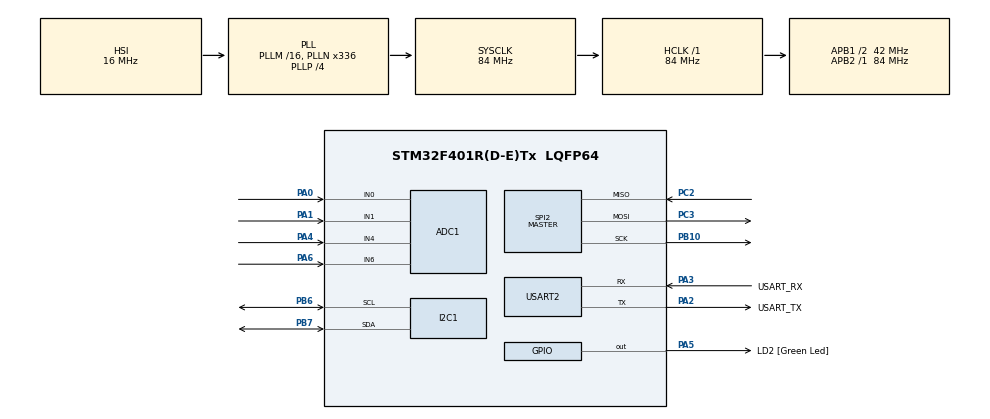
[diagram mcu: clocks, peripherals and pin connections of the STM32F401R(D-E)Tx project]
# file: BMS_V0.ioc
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ADC1.Channel-0\#ChannelRegularConversion=ADC_CHANNEL_0
ADC1.NbrOfConversionFlag=1
ADC1.Rank-0\#ChannelRegularConversion=1
ADC1.SamplingTime-0\#ChannelRegularConversion=ADC_SAMPLETIME_3CYCLES
ADC1.master=1
FREERTOS.Tasks01=Task_BMS_Main,24,128,Task_BMS_MainEntry,Default,NULL,Static,Task_BMS_MainBuffer,Task_BMS_MainControlBlock;Task_Data_Acqui,32,128,Task_Data_AcquiEntry,Default,NULL,Static,Task_Data_AcquiBuffer,Task_Data_AcquiControlBlock;Task_CAN_Tx,16,128,Task_CAN_TxEntry,Default,NULL,Static,Task_CAN_TxBuffer,Task_CAN_TxControlBlock;Task_CAN_Rx,40,128,Task_CAN_RxEntry,Default,NULL,Static,Task_CAN_RxBuffer,Task_CAN_RxControlBlock
FREERTOS.configENABLE_FPU=1
FREERTOS.configUSE_NEWLIB_REENTRANT=1
Mcu.Family=STM32F4
Mcu.Name=STM32F401R(D-E)Tx
Mcu.Package=LQFP64
NVIC.PriorityGroup=NVIC_PRIORITYGROUP_4
NVIC.TIM1_UP_TIM10_IRQn=true\:15\:0\:false\:false\:true\:false\:false\:true\:true
NVIC.TimeBase=TIM1_UP_TIM10_IRQn
NVIC.TimeBaseIP=TIM1
PA0-WKUP.Signal=ADCx_IN0
PA1.Signal=ADCx_IN1
PA13.GPIO_Label=TMS
PA13.Mode=Serial_Wire
PA13.Signal=SYS_JTMS-SWDIO
PA14.GPIO_Label=TCK
PA14.Mode=Serial_Wire
PA14.Signal=SYS_JTCK-SWCLK
PA2.GPIO_Label=USART_TX
PA2.GPIO_Mode=GPIO_MODE_AF_PP
PA2.GPIO_PuPd=GPIO_NOPULL
PA2.GPIO_Speed=GPIO_SPEED_FREQ_LOW
PA2.Mode=Asynchronous
PA2.Signal=USART2_TX
PA3.GPIO_Label=USART_RX
PA3.GPIO_Mode=GPIO_MODE_AF_PP
PA3.GPIO_PuPd=GPIO_NOPULL
PA3.GPIO_Speed=GPIO_SPEED_FREQ_LOW
PA3.Mode=Asynchronous
PA3.Signal=USART2_RX
PA4.Signal=ADCx_IN4
PA5.GPIO_Label=LD2 [Green Led]
PA5.GPIO_Mode=GPIO_MODE_OUTPUT_PP
PA5.GPIO_PuPd=GPIO_NOPULL
PA5.GPIO_Speed=GPIO_SPEED_FREQ_LOW
PA5.Signal=GPIO_Output
PA6.Signal=ADCx_IN6
PB10.Mode=Full_Duplex_Master
PB10.Signal=SPI2_SCK
PB3.GPIO_Label=SWO
PB3.Signal=SYS_JTDO-SWO
PB6.Mode=I2C
PB6.Signal=I2C1_SCL
PB7.Mode=I2C
PB7.Signal=I2C1_SDA
PC14-OSC32_IN.Mode=LSE-External-Oscillator
PC14-OSC32_IN.Signal=RCC_OSC32_IN
PC15-OSC32_OUT.Mode=LSE-External-Oscillator
PC15-OSC32_OUT.Signal=RCC_OSC32_OUT
PC2.Mode=Full_Duplex_Master
PC2.Signal=SPI2_MISO
PC3.Mode=Full_Duplex_Master
PC3.Signal=SPI2_MOSI
PH0\ -\ OSC_IN.Mode=HSE-External-Clock-Source
PH0\ -\ OSC_IN.Signal=RCC_OSC_IN
PH1\ -\ OSC_OUT.Mode=HSE-External-Clock-Source
PH1\ -\ OSC_OUT.Signal=RCC_OSC_OUT
ProjectManager.HeapSize=0x200
ProjectManager.StackSize=0x400
ProjectManager.TargetToolchain=STM32CubeIDE
RCC.48MHZClocksFreq_Value=48000000
RCC.AHBFreq_Value=84000000
RCC.APB1CLKDivider=RCC_HCLK_DIV2
RCC.APB1Freq_Value=42000000
RCC.APB1TimFreq_Value=84000000
RCC.APB2Freq_Value=84000000
RCC.APB2TimFreq_Value=84000000
RCC.CortexFreq_Value=84000000
RCC.HCLKFreq_Value=84000000
RCC.HSE_VALUE=8000000
RCC.HSI_VALUE=16000000
RCC.PLLN=336
RCC.PLLP=RCC_PLLP_DIV4
RCC.PLLQ=7
RCC.SYSCLKFreq_VALUE=84000000
RCC.SYSCLKSource=RCC_SYSCLKSOURCE_PLLCLK
RCC.VCOOutputFreq_Value=336000000
SH.ADCx_IN0.0=ADC1_IN0,IN0
SH.ADCx_IN1.0=ADC1_IN1,IN1
SH.ADCx_IN4.0=ADC1_IN4,IN4
SH.ADCx_IN6.0=ADC1_IN6,IN6
SPI2.Direction=SPI_DIRECTION_2LINES
SPI2.Mode=SPI_MODE_MASTER
SPI2.VirtualType=VM_MASTER
USART2.VirtualMode=VM_ASYNC
VP_CRC_VS_CRC.Mode=CRC_Activate
VP_FREERTOS_VS_CMSIS_V2.Mode=CMSIS_V2
VP_SYS_VS_tim1.Mode=TIM1
board=NUCLEO-F401RE

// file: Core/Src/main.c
/* USER CODE BEGIN Header */
/**
  ******************************************************************************
  * @file           : main.c
  * @brief          : Main program body
  ******************************************************************************
  * @attention
  *
  * Copyright (c) 2025 STMicroelectronics.
  * All rights reserved.
  *
  * This software is licensed under terms that can be found in the LICENSE file
  * in the root directory of this software component.
  * If no LICENSE file comes with this software, it is provided AS-IS.
  *
  ******************************************************************************
  */
/* USER CODE END Header */
#include "main.h"
#include "cmsis_os.h"

/* USER CODE BEGIN Includes */
#include "task_data_acq.h"
#include "task_bms_main.h"
#include "task_can_tx.h"
#include "task_can_rx.h"
#include "task_balance.h"
/* USER CODE END Includes */

typedef StaticTask_t osStaticThreadDef_t;

ADC_HandleTypeDef hadc1;

CRC_HandleTypeDef hcrc;

I2C_HandleTypeDef hi2c1;

SPI_HandleTypeDef hspi2;

UART_HandleTypeDef huart2;

/*============================ TASK DEFINITIONS ============================*/

/* Definitions for Task_BMS_Main */
osThreadId_t Task_BMS_MainHandle;
uint32_t Task_BMS_MainBuffer[ 128 ];
osStaticThreadDef_t Task_BMS_MainControlBlock;
const osThreadAttr_t Task_BMS_Main_attributes = {
  .name = "Task_BMS_Main",
  .cb_mem = &Task_BMS_MainControlBlock,
  .cb_size = sizeof(Task_BMS_MainControlBlock),
  .stack_mem = &Task_BMS_MainBuffer[0],
  .stack_size = sizeof(Task_BMS_MainBuffer),
  .priority = (osPriority_t) osPriorityNormal,
};

/* Definitions for Task_Data_Acqui */
osThreadId_t Task_Data_AcquisitionHandle;
uint32_t Task_Data_AcquisitionBuffer[ 128 ];
osStaticThreadDef_t Task_Data_AcquisitionControlBlock;
const osThreadAttr_t Task_Data_Acquisition_attributes = {
  .name = "Task_Data_Acquisition",
  .cb_mem = &Task_Data_AcquisitionControlBlock,
  .cb_size = sizeof(Task_Data_AcquisitionControlBlock),
  .stack_mem = &Task_Data_AcquisitionBuffer[0],
  .stack_size = sizeof(Task_Data_AcquisitionBuffer),
  .priority = (osPriority_t) osPriorityAboveNormal,
};

/* Definitions for Task_CAN_Tx */
osThreadId_t Task_CAN_TxHandle;
uint32_t Task_CAN_TxBuffer[ 128 ];
osStaticThreadDef_t Task_CAN_TxControlBlock;
const osThreadAttr_t Task_CAN_Tx_attributes = {
  .name = "Task_CAN_Tx",
  .cb_mem = &Task_CAN_TxControlBlock,
  .cb_size = sizeof(Task_CAN_TxControlBlock),
  .stack_mem = &Task_CAN_TxBuffer[0],
  .stack_size = sizeof(Task_CAN_TxBuffer),
  .priority = (osPriority_t) osPriorityBelowNormal,
};

/* Definitions for Task_CAN_Rx */
osThreadId_t Task_CAN_RxHandle;
uint32_t Task_CAN_RxBuffer[ 128 ];
osStaticThreadDef_t Task_CAN_RxControlBlock;
const osThreadAttr_t Task_CAN_Rx_attributes = {
  .name = "Task_CAN_Rx",
  .cb_mem = &Task_CAN_RxControlBlock,
  .cb_size = sizeof(Task_CAN_RxControlBlock),
  .stack_mem = &Task_CAN_RxBuffer[0],
  .stack_size = sizeof(Task_CAN_RxBuffer),
  .priority = (osPriority_t) osPriorityHigh,
};

/* Definitions for Task_Balance */
osThreadId_t Task_BalanceHandle;
uint32_t Task_BalanceBuffer[ 128 ];
osStaticThreadDef_t Task_BalanceControlBlock;
const osThreadAttr_t Task_Balance_attributes = {
        .name = "Task_Balance",
        .cb_mem = &Task_BalanceControlBlock,
        .cb_size = sizeof(Task_BalanceControlBlock),
        .stack_mem = &Task_BalanceBuffer[0],
        .stack_size = sizeof(Task_BalanceBuffer),
        .priority = (osPriority_t) osPriorityNormal,
};

void SystemClock_Config(void);
static void MX_GPIO_Init(void);
static void MX_ADC1_Init(void);
static void MX_CRC_Init(void);
static void MX_I2C1_Init(void);
static void MX_SPI2_Init(void);
static void MX_USART2_UART_Init(void);
void Task_BMS_MainEntry(void *argument);
void Task_Data_AcquiEntry(void *argument);
void Task_CAN_TxEntry(void *argument);
void Task_CAN_RxEntry(void *argument);

int main(void)
{

  /* MCU Configuration--------------------------------------------------------*/

  /* Reset of all peripherals, Initializes the Flash interface and the Systick. */
  HAL_Init();

  /* Configure the system clock */
  SystemClock_Config();

  /* Initialize all configured peripherals */
  MX_GPIO_Init();
  MX_ADC1_Init();
  MX_CRC_Init();
  MX_I2C1_Init();
  MX_SPI2_Init();
  MX_USART2_UART_Init();

  /* Init scheduler */
  osKernelInitialize();
  /* creation of Task_BMS_Main */
  Task_BMS_MainHandle = osThreadNew(Task_BMS_Main, NULL, &Task_BMS_Main_attributes);

  /* creation of Task_Data_Acqui */
  Task_Data_AcquisitionHandle = osThreadNew(Task_Data_Acquisition, NULL, &Task_Data_Acquisition_attributes);

  /* creation of Task_CAN_Tx */
  Task_CAN_TxHandle = osThreadNew(Task_CAN_Tx, NULL, &Task_CAN_Tx_attributes);

  /* creation of Task_CAN_Rx */
  Task_CAN_RxHandle = osThreadNew(Task_CAN_Rx, NULL, &Task_CAN_Rx_attributes);

  /* creation of Task_Balance */
  Task_BalanceHandle = osThreadNew(Task_Balance, NULL, &Task_Balance_attributes);

  /* Start scheduler */
  osKernelStart();

  /* We should never get here as control is now taken by the scheduler */
  /* Infinite loop */
  while (1)
  {

  }
}

void SystemClock_Config(void)
{
  RCC_OscInitTypeDef RCC_OscInitStruct = {0};
  RCC_ClkInitTypeDef RCC_ClkInitStruct = {0};

  /** Configure the main internal regulator output voltage
  */
  __HAL_RCC_PWR_CLK_ENABLE();
  __HAL_PWR_VOLTAGESCALING_CONFIG(PWR_REGULATOR_VOLTAGE_SCALE2);

  /** Initializes the RCC Oscillators according to the specified parameters
  * in the RCC_OscInitTypeDef structure.
  */
  RCC_OscInitStruct.OscillatorType = RCC_OSCILLATORTYPE_HSI;
  RCC_OscInitStruct.HSIState = RCC_HSI_ON;
  RCC_OscInitStruct.HSICalibrationValue = RCC_HSICALIBRATION_DEFAULT;
  RCC_OscInitStruct.PLL.PLLState = RCC_PLL_ON;
  RCC_OscInitStruct.PLL.PLLSource = RCC_PLLSOURCE_HSI;
  RCC_OscInitStruct.PLL.PLLM = 16;
  RCC_OscInitStruct.PLL.PLLN = 336;
  RCC_OscInitStruct.PLL.PLLP = RCC_PLLP_DIV4;
  RCC_OscInitStruct.PLL.PLLQ = 7;
  if (HAL_RCC_OscConfig(&RCC_OscInitStruct) != HAL_OK)
  {
    Error_Handler();
  }

  /** Initializes the CPU, AHB and APB buses clocks
  */
  RCC_ClkInitStruct.ClockType = RCC_CLOCKTYPE_HCLK|RCC_CLOCKTYPE_SYSCLK
                              |RCC_CLOCKTYPE_PCLK1|RCC_CLOCKTYPE_PCLK2;
  RCC_ClkInitStruct.SYSCLKSource = RCC_SYSCLKSOURCE_PLLCLK;
  RCC_ClkInitStruct.AHBCLKDivider = RCC_SYSCLK_DIV1;
  RCC_ClkInitStruct.APB1CLKDivider = RCC_HCLK_DIV2;
  RCC_ClkInitStruct.APB2CLKDivider = RCC_HCLK_DIV1;

  if (HAL_RCC_ClockConfig(&RCC_ClkInitStruct, FLASH_LATENCY_2) != HAL_OK)
  {
    Error_Handler();
  }
}

static void MX_ADC1_Init(void)
{

  ADC_ChannelConfTypeDef sConfig = {0};

  /** Configure the global features of the ADC (Clock, Resolution, Data Alignment and number of conversion)
  */
  hadc1.Instance = ADC1;
  hadc1.Init.ClockPrescaler = ADC_CLOCK_SYNC_PCLK_DIV4;
  hadc1.Init.Resolution = ADC_RESOLUTION_12B;
  hadc1.Init.ScanConvMode = DISABLE;
  hadc1.Init.ContinuousConvMode = DISABLE;
  hadc1.Init.DiscontinuousConvMode = DISABLE;
  hadc1.Init.ExternalTrigConvEdge = ADC_EXTERNALTRIGCONVEDGE_NONE;
  hadc1.Init.ExternalTrigConv = ADC_SOFTWARE_START;
  hadc1.Init.DataAlign = ADC_DATAALIGN_RIGHT;
  hadc1.Init.NbrOfConversion = 1;
  hadc1.Init.DMAContinuousRequests = DISABLE;
  hadc1.Init.EOCSelection = ADC_EOC_SINGLE_CONV;
  if (HAL_ADC_Init(&hadc1) != HAL_OK)
  {
    Error_Handler();
  }

  /** Configure for the selected ADC regular channel its corresponding rank in the sequencer and its sample time.
  */
  sConfig.Channel = ADC_CHANNEL_0;
  sConfig.Rank = 1;
  sConfig.SamplingTime = ADC_SAMPLETIME_3CYCLES;
  if (HAL_ADC_ConfigChannel(&hadc1, &sConfig) != HAL_OK)
  {
    Error_Handler();
  }

}

static void MX_CRC_Init(void)
{

  hcrc.Instance = CRC;
  if (HAL_CRC_Init(&hcrc) != HAL_OK)
  {
    Error_Handler();
  }

}

static void MX_I2C1_Init(void)
{

  hi2c1.Instance = I2C1;
  hi2c1.Init.ClockSpeed = 100000;
  hi2c1.Init.DutyCycle = I2C_DUTYCYCLE_2;
  hi2c1.Init.OwnAddress1 = 0;
  hi2c1.Init.AddressingMode = I2C_ADDRESSINGMODE_7BIT;
  hi2c1.Init.DualAddressMode = I2C_DUALADDRESS_DISABLE;
  hi2c1.Init.OwnAddress2 = 0;
  hi2c1.Init.GeneralCallMode = I2C_GENERALCALL_DISABLE;
  hi2c1.Init.NoStretchMode = I2C_NOSTRETCH_DISABLE;
  if (HAL_I2C_Init(&hi2c1) != HAL_OK)
  {
    Error_Handler();
  }

}

static void MX_SPI2_Init(void)
{

  /* SPI2 parameter configuration*/
  hspi2.Instance = SPI2;
  hspi2.Init.Mode = SPI_MODE_MASTER;
  hspi2.Init.Direction = SPI_DIRECTION_2LINES;
  hspi2.Init.DataSize = SPI_DATASIZE_8BIT;
  hspi2.Init.CLKPolarity = SPI_POLARITY_LOW;
  hspi2.Init.CLKPhase = SPI_PHASE_1EDGE;
  hspi2.Init.NSS = SPI_NSS_SOFT;
  hspi2.Init.BaudRatePrescaler = SPI_BAUDRATEPRESCALER_2;
  hspi2.Init.FirstBit = SPI_FIRSTBIT_MSB;
  hspi2.Init.TIMode = SPI_TIMODE_DISABLE;
  hspi2.Init.CRCCalculation = SPI_CRCCALCULATION_DISABLE;
  hspi2.Init.CRCPolynomial = 10;
  if (HAL_SPI_Init(&hspi2) != HAL_OK)
  {
    Error_Handler();
  }

}

static void MX_USART2_UART_Init(void)
{

  huart2.Instance = USART2;
  huart2.Init.BaudRate = 115200;
  huart2.Init.WordLength = UART_WORDLENGTH_8B;
  huart2.Init.StopBits = UART_STOPBITS_1;
  huart2.Init.Parity = UART_PARITY_NONE;
  huart2.Init.Mode = UART_MODE_TX_RX;
  huart2.Init.HwFlowCtl = UART_HWCONTROL_NONE;
  huart2.Init.OverSampling = UART_OVERSAMPLING_16;
  if (HAL_UART_Init(&huart2) != HAL_OK)
  {
    Error_Handler();
  }

}

static void MX_GPIO_Init(void)
{
  GPIO_InitTypeDef GPIO_InitStruct = {0};

  /* GPIO Ports Clock Enable */
  __HAL_RCC_GPIOC_CLK_ENABLE();
  __HAL_RCC_GPIOH_CLK_ENABLE();
  __HAL_RCC_GPIOA_CLK_ENABLE();
  __HAL_RCC_GPIOB_CLK_ENABLE();

  /*Configure GPIO pin Output Level */
  HAL_GPIO_WritePin(LD2_GPIO_Port, LD2_Pin, GPIO_PIN_RESET);

  /*Configure GPIO pin : LD2_Pin */
  GPIO_InitStruct.Pin = LD2_Pin;
  GPIO_InitStruct.Mode = GPIO_MODE_OUTPUT_PP;
  GPIO_InitStruct.Pull = GPIO_NOPULL;
  GPIO_InitStruct.Speed = GPIO_SPEED_FREQ_LOW;
  HAL_GPIO_Init(LD2_GPIO_Port, &GPIO_InitStruct);

}

void HAL_TIM_PeriodElapsedCallback(TIM_HandleTypeDef *htim)
{
  if (htim->Instance == TIM1) {
    HAL_IncTick();
  }
}

void Error_Handler(void)
{
  __disable_irq();
  while (1)
  {
  }
}
